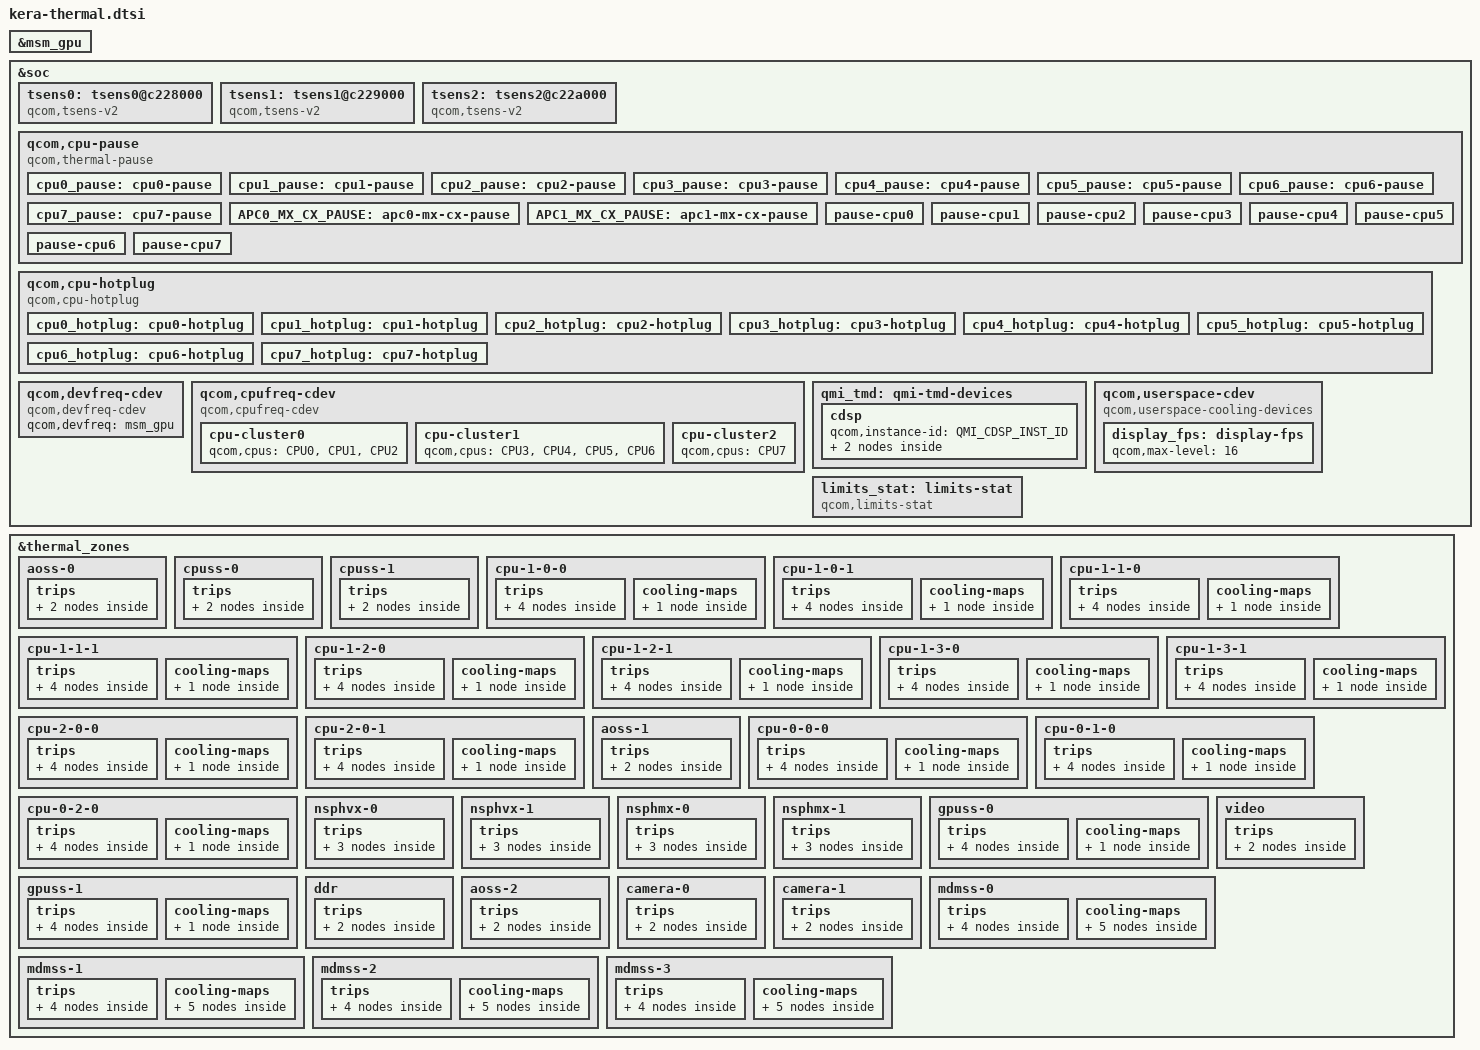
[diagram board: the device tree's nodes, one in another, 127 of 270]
// SPDX-License-Identifier: BSD-3-Clause
/*
 * Copyright (c) 2024-2025 Qualcomm Innovation Center, Inc. All rights reserved.
 */

#include <dt-bindings/thermal/thermal_qti.h>

&msm_gpu {
	#cooling-cells = <2>;
};

&soc {
	tsens0: tsens0@c228000 {
		compatible = "qcom,tsens-v2";
		reg = <0xc228000 0x1ff>, /* TM */
			  <0xc222000 0x1ff>; /* SROT */
		#qcom,sensors = <13>;
		interrupts = <GIC_SPI 506 IRQ_TYPE_LEVEL_HIGH>,
			<GIC_SPI 560 IRQ_TYPE_LEVEL_HIGH>;
		interrupt-names = "uplow","critical";
		#thermal-sensor-cells = <1>;
	};

	tsens1: tsens1@c229000 {
		compatible = "qcom,tsens-v2";
		reg = <0xc229000 0x1ff>, /* TM */
			  <0xc223000 0x1ff>; /* SROT */
		#qcom,sensors = <14>;
		interrupts = <GIC_SPI 507 IRQ_TYPE_LEVEL_HIGH>,
			<GIC_SPI 561 IRQ_TYPE_LEVEL_HIGH>;
		interrupt-names = "uplow","critical";
		#thermal-sensor-cells = <1>;
	};

	tsens2: tsens2@c22a000 {
		compatible = "qcom,tsens-v2";
		reg = <0xc22a000 0x1ff>, /* TM */
			  <0xc224000 0x1ff>; /* SROT */
		#qcom,sensors = <5>;
		interrupts = <GIC_SPI 508 IRQ_TYPE_LEVEL_HIGH>,
			<GIC_SPI 562 IRQ_TYPE_LEVEL_HIGH>;
		interrupt-names = "uplow","critical";
		#thermal-sensor-cells = <1>;
	};

	qcom,cpu-pause {
		compatible = "qcom,thermal-pause";

		cpu0_pause: cpu0-pause {
			qcom,cpus = <&CPU0>;
			qcom,cdev-alias = "thermal-pause-1";
			#cooling-cells = <2>;
		};

		cpu1_pause: cpu1-pause {
			qcom,cpus = <&CPU1>;
			qcom,cdev-alias = "thermal-pause-2";
			#cooling-cells = <2>;
		};

		cpu2_pause: cpu2-pause {
			qcom,cpus = <&CPU2>;
			qcom,cdev-alias = "thermal-pause-4";
			#cooling-cells = <2>;
		};

		cpu3_pause: cpu3-pause {
			qcom,cpus = <&CPU3>;
			qcom,cdev-alias = "thermal-pause-8";
			#cooling-cells = <2>;
		};

		cpu4_pause: cpu4-pause {
			qcom,cpus = <&CPU4>;
			qcom,cdev-alias = "thermal-pause-10";
			#cooling-cells = <2>;
		};

		cpu5_pause: cpu5-pause {
			qcom,cpus = <&CPU5>;
			qcom,cdev-alias = "thermal-pause-20";
			#cooling-cells = <2>;
		};

		cpu6_pause: cpu6-pause {
			qcom,cpus = <&CPU6>;
			qcom,cdev-alias = "thermal-pause-40";
			#cooling-cells = <2>;
		};

		cpu7_pause: cpu7-pause {
			qcom,cpus = <&CPU7>;
			qcom,cdev-alias = "thermal-pause-80";
			#cooling-cells = <2>;
		};

		APC0_MX_CX_PAUSE: apc0-mx-cx-pause {
			qcom,cpus = <&CPU2 &CPU3 &CPU4 &CPU5>;
			qcom,cdev-alias = "thermal-pause-3C";
			#cooling-cells = <2>;
		};

		APC1_MX_CX_PAUSE: apc1-mx-cx-pause {
			qcom,cpus = <&CPU6 &CPU7>;
			qcom,cdev-alias = "thermal-pause-C0";
			#cooling-cells = <2>;
		};

		/* Thermal-engine cooling devices */
		pause-cpu0 {
			qcom,cpus = <&CPU0>;
			qcom,cdev-alias = "pause-cpu0";
		};

		pause-cpu1 {
			qcom,cpus = <&CPU1>;
			qcom,cdev-alias = "pause-cpu1";
		};

		pause-cpu2 {
			qcom,cpus = <&CPU2>;
			qcom,cdev-alias = "pause-cpu2";
		};

		pause-cpu3 {
			qcom,cpus = <&CPU3>;
			qcom,cdev-alias = "pause-cpu3";
		};

		pause-cpu4 {
			qcom,cpus = <&CPU4>;
			qcom,cdev-alias = "pause-cpu4";
		};

		pause-cpu5 {
			qcom,cpus = <&CPU5>;
			qcom,cdev-alias = "pause-cpu5";
		};

		pause-cpu6 {
			qcom,cpus = <&CPU6>;
			qcom,cdev-alias = "pause-cpu6";
		};

		pause-cpu7 {
			qcom,cpus = <&CPU7>;
			qcom,cdev-alias = "pause-cpu7";
		};
	};

	qcom,cpu-hotplug {
		compatible = "qcom,cpu-hotplug";

		cpu0_hotplug: cpu0-hotplug {
			qcom,cpu = <&CPU0>;
			qcom,cdev-alias = "cpu-hotplug0";
			#cooling-cells = <2>;
		};

		cpu1_hotplug: cpu1-hotplug {
			qcom,cpu = <&CPU1>;
			qcom,cdev-alias = "cpu-hotplug1";
			#cooling-cells = <2>;
		};

		cpu2_hotplug: cpu2-hotplug {
			qcom,cpu = <&CPU2>;
			qcom,cdev-alias = "cpu-hotplug2";
			#cooling-cells = <2>;
		};

		cpu3_hotplug: cpu3-hotplug {
			qcom,cpu = <&CPU3>;
			qcom,cdev-alias = "cpu-hotplug3";
			#cooling-cells = <2>;
		};

		cpu4_hotplug: cpu4-hotplug {
			qcom,cpu = <&CPU4>;
			qcom,cdev-alias = "cpu-hotplug4";
			#cooling-cells = <2>;
		};

		cpu5_hotplug: cpu5-hotplug {
			qcom,cpu = <&CPU5>;
			qcom,cdev-alias = "cpu-hotplug5";
			#cooling-cells = <2>;
		};

		cpu6_hotplug: cpu6-hotplug {
			qcom,cpu = <&CPU6>;
			qcom,cdev-alias = "cpu-hotplug6";
			#cooling-cells = <2>;
		};

		cpu7_hotplug: cpu7-hotplug {
			qcom,cpu = <&CPU7>;
			qcom,cdev-alias = "cpu-hotplug7";
			#cooling-cells = <2>;
		};
	};

	qcom,devfreq-cdev {
		compatible = "qcom,devfreq-cdev";
		qcom,devfreq = <&msm_gpu>;
	};

	qcom,cpufreq-cdev {
		compatible = "qcom,cpufreq-cdev";

		cpu-cluster0 {
			qcom,cpus = <&CPU0 &CPU1 &CPU2>;
		};

		cpu-cluster1 {
			qcom,cpus = <&CPU3 &CPU4 &CPU5 &CPU6>;
		};

		cpu-cluster2 {
			qcom,cpus = <&CPU7>;
		};
	};

	qmi_tmd: qmi-tmd-devices {
		cdsp {
			qcom,instance-id = <QMI_CDSP_INST_ID>;

			cdsp_sw: cdsp {
				qcom,qmi-dev-name = "cdsp_sw";
				#cooling-cells = <2>;
			};

			cdsp_hw: cdsp_hw {
				qcom,qmi-dev-name = "cdsp_hw";
				#cooling-cells = <2>;
			};
		};
	};

	qcom,userspace-cdev {
		compatible = "qcom,userspace-cooling-devices";

		display_fps: display-fps {
			qcom,max-level = <16>;
			#cooling-cells = <2>;
		};
	};

	limits_stat: limits-stat {
		compatible = "qcom,limits-stat";
		qcom,limits-stat-sensor-names = "aoss-0", "cpuss-0", "cpuss-1",
						"cpu-1-0-0", "cpu-1-0-1", "cpu-1-1-0",
						"cpu-1-1-1", "cpu-1-2-0", "cpu-1-2-1",
						"cpu-1-3-0", "cpu-1-3-1", "cpu-2-0-0", "cpu-2-0-1",
						"aoss-1", "cpu-0-0-0", "cpu-0-1-0", "cpu-0-2-0",
						"nsphvx-0", "nsphvx-1", "nsphmx-0", "nsphmx-1",
						"gpuss-0", "gpuss-1", "video", "ddr", "camera-0",
						"camera-1", "aoss-2", "mdmss-0", "mdmss-1",
						"mdmss-2", "mdmss-3";
	};
};

#include "sun-thermal-modem.dtsi"

&thermal_zones {
	aoss-0 {
		polling-delay-passive = <0>;
		polling-delay = <0>;
		thermal-sensors = <&tsens0 0>;

		trips {
			trip-point0 {
				temperature = <125000>;
				hysteresis = <1000>;
				type = "passive";
			};

			trip-point1 {
				temperature = <115000>;
				hysteresis = <0>;
				type = "hot";
			};
		};
	};

	cpuss-0 {
		polling-delay-passive = <0>;
		polling-delay = <0>;
		thermal-sensors = <&tsens0 1>;

		trips {
			trip-point0 {
				temperature = <125000>;
				hysteresis = <1000>;
				type = "passive";
			};

			trip-point1 {
				temperature = <115000>;
				hysteresis = <0>;
				type = "hot";
			};
		};
	};

	cpuss-1 {
		polling-delay-passive = <0>;
		polling-delay = <0>;
		thermal-sensors = <&tsens0 2>;

		trips {
			trip-point0 {
				temperature = <125000>;
				hysteresis = <1000>;
				type = "passive";
			};

			trip-point1 {
				temperature = <115000>;
				hysteresis = <0>;
				type = "hot";
			};
		};
	};

	cpu-1-0-0 {
		polling-delay-passive = <0>;
		polling-delay = <0>;
		thermal-sensors = <&tsens0 3>;

		trips {
			trip-point0 {
				temperature = <125000>;
				hysteresis = <1000>;
				type = "passive";
			};

			trip-point1 {
				temperature = <125000>;
				hysteresis = <1000>;
				type = "passive";
			};

			cpu2_emerg0: cpu2-emerg0-cfg {
				temperature = <110000>;
				hysteresis = <10000>;
				type = "passive";
			};

			trip-point2 {
				temperature = <115000>;
				hysteresis = <0>;
				type = "hot";
			};
		};

		cooling-maps {
			cpu100_cdev {
				trip = <&cpu2_emerg0>;
				cooling-device = <&cpu2_pause 1 1>;
			};
		};
	};

	cpu-1-0-1 {
		polling-delay-passive = <0>;
		polling-delay = <0>;
		thermal-sensors = <&tsens0 4>;

		trips {
			trip-point0 {
				temperature = <125000>;
				hysteresis = <1000>;
				type = "passive";
			};

			trip-point1 {
				temperature = <125000>;
				hysteresis = <1000>;
				type = "passive";
			};

			cpu2_emerg1: cpu2-emerg1-cfg {
				temperature = <110000>;
				hysteresis = <10000>;
				type = "passive";
			};

			trip-point2 {
				temperature = <115000>;
				hysteresis = <0>;
				type = "hot";
			};
		};

		cooling-maps {
			cpu101_cdev {
				trip = <&cpu2_emerg1>;
				cooling-device = <&cpu2_pause 1 1>;
			};
		};
	};


	cpu-1-1-0 {
		polling-delay-passive = <0>;
		polling-delay = <0>;
		thermal-sensors = <&tsens0 5>;

		trips {
			trip-point0 {
				temperature = <125000>;
				hysteresis = <1000>;
				type = "passive";
			};

			trip-point1 {
				temperature = <125000>;
				hysteresis = <1000>;
				type = "passive";
			};

			cpu3_emerg0: cpu3-emerg0-cfg {
				temperature = <110000>;
				hysteresis = <10000>;
				type = "passive";
			};

			trip-point2 {
				temperature = <115000>;
				hysteresis = <0>;
				type = "hot";
			};
		};

		cooling-maps {
			cpu110_cdev {
				trip = <&cpu3_emerg0>;
				cooling-device = <&cpu3_pause 1 1>;
			};
		};
	};

	cpu-1-1-1 {
		polling-delay-passive = <0>;
		polling-delay = <0>;
		thermal-sensors = <&tsens0 6>;

		trips {
			trip-point0 {
				temperature = <125000>;
				hysteresis = <1000>;
				type = "passive";
			};

			trip-point1 {
				temperature = <125000>;
				hysteresis = <1000>;
				type = "passive";
			};

			cpu3_emerg1: cpu3-emerg1-cfg {
				temperature = <110000>;
				hysteresis = <10000>;
				type = "passive";
			};

			trip-point2 {
				temperature = <115000>;
				hysteresis = <0>;
				type = "hot";
			};
		};

		cooling-maps {
			cpu111_cdev {
				trip = <&cpu3_emerg1>;
				cooling-device = <&cpu3_pause 1 1>;
			};
		};
	};

	cpu-1-2-0 {
		polling-delay-passive = <0>;
		polling-delay = <0>;
		thermal-sensors = <&tsens0 7>;

		trips {
			trip-point0 {
				temperature = <125000>;
				hysteresis = <1000>;
				type = "passive";
			};

			trip-point1 {
				temperature = <125000>;
				hysteresis = <1000>;
				type = "passive";
			};

			cpu4_emerg0: cpu4-emerg0-cfg {
				temperature = <110000>;
				hysteresis = <10000>;
				type = "passive";
			};

			trip-point2 {
				temperature = <115000>;
				hysteresis = <0>;
				type = "hot";
			};
		};

		cooling-maps {
			cpu120_cdev {
				trip = <&cpu4_emerg0>;
				cooling-device = <&cpu4_pause 1 1>;
			};
		};
	};

	cpu-1-2-1 {
		polling-delay-passive = <0>;
		polling-delay = <0>;
		thermal-sensors = <&tsens0 8>;

		trips {
			trip-point0 {
				temperature = <125000>;
				hysteresis = <1000>;
				type = "passive";
			};

			trip-point1 {
				temperature = <125000>;
				hysteresis = <1000>;
				type = "passive";
			};

			cpu4_emerg1: cpu4-emerg1-cfg {
				temperature = <110000>;
				hysteresis = <10000>;
				type = "passive";
			};

			trip-point2 {
				temperature = <115000>;
				hysteresis = <0>;
				type = "hot";
			};
		};

		cooling-maps {
			cpu121_cdev {
				trip = <&cpu4_emerg1>;
				cooling-device = <&cpu4_pause 1 1>;
			};
		};
	};

	cpu-1-3-0 {
		polling-delay-passive = <0>;
		polling-delay = <0>;
		thermal-sensors = <&tsens0 9>;

		trips {
			trip-point0 {
				temperature = <125000>;
				hysteresis = <1000>;
				type = "passive";
			};

			trip-point1 {
				temperature = <125000>;
				hysteresis = <1000>;
				type = "passive";
			};

			cpu5_emerg0: cpu5-emerg0-cfg {
				temperature = <110000>;
				hysteresis = <10000>;
				type = "passive";
			};

			trip-point4 {
				temperature = <115000>;
				hysteresis = <0>;
				type = "hot";
			};
		};

		cooling-maps {
			cpu130_cdev {
				trip = <&cpu5_emerg0>;
				cooling-device = <&cpu5_pause 1 1>;
			};
		};
	};

	cpu-1-3-1 {
		polling-delay-passive = <0>;
		polling-delay = <0>;
		thermal-sensors = <&tsens0 10>;

		trips {
			trip-point0 {
				temperature = <125000>;
				hysteresis = <1000>;
				type = "passive";
			};

			trip-point1 {
				temperature = <125000>;
				hysteresis = <1000>;
				type = "passive";
			};

			cpu5_emerg1: cpu5-emerg1-cfg {
				temperature = <110000>;
				hysteresis = <10000>;
				type = "passive";
			};

			trip-point2 {
				temperature = <115000>;
				hysteresis = <0>;
				type = "hot";
			};
		};

		cooling-maps {
			cpu131_cdev {
				trip = <&cpu5_emerg1>;
				cooling-device = <&cpu5_pause 1 1>;
			};
		};
	};

	cpu-2-0-0 {
		polling-delay-passive = <0>;
		polling-delay = <0>;
		thermal-sensors = <&tsens0 11>;

		trips {
			trip-point0 {
				temperature = <125000>;
				hysteresis = <1000>;
				type = "passive";
			};

			trip-point1 {
				temperature = <125000>;
				hysteresis = <1000>;
				type = "passive";
			};

			cpu7_emerg0: cpu7-emerg0-cfg {
				temperature = <110000>;
				hysteresis = <10000>;
				type = "passive";
			};

			trip-point2 {
				temperature = <115000>;
				hysteresis = <0>;
				type = "hot";
			};
		};

		cooling-maps {
			cpu200_cdev {
				trip = <&cpu7_emerg0>;
				cooling-device = <&cpu7_pause 1 1>;
			};
		};
	};

	cpu-2-0-1 {
		polling-delay-passive = <0>;
		polling-delay = <0>;
		thermal-sensors = <&tsens0 12>;

		trips {
			trip-point0 {
				temperature = <125000>;
				hysteresis = <1000>;
				type = "passive";
			};

			trip-point1 {
				temperature = <125000>;
				hysteresis = <1000>;
				type = "passive";
			};

			cpu7_emerg1: cpu7-emerg0-cfg {
				temperature = <110000>;
				hysteresis = <10000>;
				type = "passive";
			};

			trip-point2 {
				temperature = <115000>;
				hysteresis = <0>;
				type = "hot";
			};
		};

		cooling-maps {
			cpu201_cdev {
				trip = <&cpu7_emerg1>;
				cooling-device = <&cpu7_pause 1 1>;
			};
		};
	};

	aoss-1 {
		polling-delay-passive = <0>;
		polling-delay = <0>;
		thermal-sensors = <&tsens1 0>;

		trips {
			trip-point0 {
				temperature = <125000>;
				hysteresis = <1000>;
				type = "passive";
			};

			trip-point1 {
				temperature = <115000>;
				hysteresis = <0>;
				type = "hot";
			};
		};
	};

	cpu-0-0-0 {
		polling-delay-passive = <0>;
		polling-delay = <0>;
		thermal-sensors = <&tsens1 1>;

		trips {
			trip-point0 {
				temperature = <125000>;
				hysteresis = <1000>;
				type = "passive";
			};

			trip-point1 {
				temperature = <125000>;
				hysteresis = <1000>;
				type = "passive";
			};

			cpu0_emerg0: cpu0-emerg0-cfg {
				temperature = <110000>;
				hysteresis = <10000>;
				type = "passive";
			};

			trip-point2 {
				temperature = <115000>;
				hysteresis = <0>;
				type = "hot";
			};
		};

		cooling-maps {
			cpu000_cdev {
				trip = <&cpu0_emerg0>;
				cooling-device = <&cpu0_pause 1 1>;
			};
		};
	};

	cpu-0-1-0 {
		polling-delay-passive = <0>;
		polling-delay = <0>;
		thermal-sensors = <&tsens1 2>;

		trips {
			trip-point0 {
				temperature = <125000>;
				hysteresis = <1000>;
				type = "passive";
			};

			trip-point1 {
				temperature = <125000>;
				hysteresis = <1000>;
				type = "passive";
			};

			cpu1_emerg0: cpu1-emerg0-cfg {
				temperature = <110000>;
				hysteresis = <10000>;
				type = "passive";
			};

			trip-point2 {
				temperature = <115000>;
				hysteresis = <0>;
				type = "hot";
			};
		};

		cooling-maps {
			cpu010_cdev {
				trip = <&cpu1_emerg0>;
				cooling-device = <&cpu1_pause 1 1>;
			};
		};
	};

	cpu-0-2-0 {
		polling-delay-passive = <0>;
		polling-delay = <0>;
		thermal-sensors = <&tsens1 3>;

		trips {
			trip-point0 {
				temperature = <125000>;
				hysteresis = <1000>;
				type = "passive";
			};

			trip-point1 {
				temperature = <125000>;
				hysteresis = <1000>;
				type = "passive";
			};

			cpu6_emerg0: cpu6-emerg0-cfg {
				temperature = <110000>;
				hysteresis = <10000>;
				type = "passive";
			};

			trip-point2 {
				temperature = <115000>;
				hysteresis = <0>;
				type = "hot";
			};
		};

		cooling-maps {
			cpu140_cdev {
				trip = <&cpu6_emerg0>;
				cooling-device = <&cpu6_pause 1 1>;
			};
		};
	};

	nsphvx-0 {
		polling-delay-passive = <0>;
		polling-delay = <0>;
		thermal-sensors = <&tsens1 4>;

		trips {
			trip-point0 {
				temperature = <125000>;
				hysteresis = <1000>;
				type = "passive";
			};

			trip-point1 {
				temperature = <125000>;
				hysteresis = <1000>;
				type = "passive";
			};

			trip-point2 {
				temperature = <115000>;
				hysteresis = <0>;
				type = "hot";
			};
		};
	};

	nsphvx-1 {
		polling-delay-passive = <0>;
		polling-delay = <0>;
		thermal-sensors = <&tsens1 5>;

		trips {
			trip-point0 {
				temperature = <125000>;
				hysteresis = <1000>;
				type = "passive";
			};

			trip-point1 {
				temperature = <125000>;
				hysteresis = <1000>;
				type = "passive";
			};

			trip-point2 {
				temperature = <115000>;
				hysteresis = <0>;
				type = "hot";
			};
		};
	};

	nsphmx-0 {
		polling-delay-passive = <0>;
		polling-delay = <0>;
		thermal-sensors = <&tsens1 6>;

		trips {
			trip-point0 {
				temperature = <125000>;
				hysteresis = <1000>;
				type = "passive";
			};

			trip-point1 {
				temperature = <125000>;
				hysteresis = <1000>;
				type = "passive";
			};

			trip-point2 {
				temperature = <115000>;
				hysteresis = <0>;
				type = "hot";
			};
		};
	};

	nsphmx-1 {
		polling-delay-passive = <0>;
		polling-delay = <0>;
		thermal-sensors = <&tsens1 7>;

		trips {
			trip-point0 {
				temperature = <125000>;
				hysteresis = <1000>;
				type = "passive";
			};

			trip-point1 {
				temperature = <125000>;
				hysteresis = <1000>;
				type = "passive";
			};

			trip-point2 {
				temperature = <115000>;
				hysteresis = <0>;
				type = "hot";
			};
		};
	};


	gpuss-0 {
		polling-delay-passive = <10>;
		polling-delay = <0>;
		thermal-sensors = <&tsens1 8>;

		trips {
			trip-point0 {
				temperature = <125000>;
				hysteresis = <1000>;
				type = "passive";
			};

			trip-point1 {
				temperature = <125000>;
				hysteresis = <1000>;
				type = "passive";
			};

			gpu0_tj_cfg: tj_cfg {
				temperature = <95000>;
				hysteresis = <5000>;
				type = "passive";
			};

			trip-point2 {
				temperature = <115000>;
				hysteresis = <0>;
				type = "hot";
			};
		};

		cooling-maps {
			gpu0_cdev {
				trip = <&gpu0_tj_cfg>;
				cooling-device = <&msm_gpu 0 THERMAL_NO_LIMIT>;
			};
		};
	};

	gpuss-1 {
		polling-delay-passive = <10>;
		polling-delay = <0>;
		thermal-sensors = <&tsens1 9>;

		trips {
			trip-point0 {
				temperature = <125000>;
				hysteresis = <1000>;
				type = "passive";
			};

			trip-point1 {
				temperature = <125000>;
				hysteresis = <1000>;
				type = "passive";
			};

			gpu1_tj_cfg: tj_cfg {
				temperature = <95000>;
				hysteresis = <5000>;
				type = "passive";
			};

			trip-point2 {
				temperature = <115000>;
				hysteresis = <0>;
				type = "hot";
			};
		};

		cooling-maps {
			gpu1_cdev {
				trip = <&gpu1_tj_cfg>;
				cooling-device = <&msm_gpu 0 THERMAL_NO_LIMIT>;
			};
		};
	};

	video {
		polling-delay-passive = <0>;
		polling-delay = <0>;
		thermal-sensors = <&tsens1 10>;

		trips {
			trip-point0 {
				temperature = <125000>;
				hysteresis = <1000>;
				type = "passive";
			};

			trip-point1 {
				temperature = <115000>;
				hysteresis = <0>;
				type = "hot";
			};

		};
	};

	ddr {
		polling-delay-passive = <0>;
		polling-delay = <0>;
		thermal-sensors = <&tsens1 11>;

		trips {
			trip-point0 {
				temperature = <125000>;
				hysteresis = <1000>;
				type = "passive";
			};

			trip-point1 {
				temperature = <115000>;
				hysteresis = <0>;
				type = "hot";
			};
		};
	};

	aoss-2 {
		polling-delay-passive = <0>;
		polling-delay = <0>;
		thermal-sensors = <&tsens2 0>;

		trips {
			trip-point0 {
				temperature = <125000>;
				hysteresis = <1000>;
				type = "passive";
			};

			trip-point1 {
				temperature = <115000>;
				hysteresis = <0>;
				type = "hot";
			};
		};
	};

	camera-0 {
		polling-delay-passive = <0>;
		polling-delay = <0>;
		thermal-sensors = <&tsens1 12>;

		trips {
			trip-point0 {
				temperature = <125000>;
				hysteresis = <1000>;
				type = "passive";
			};

			trip-point1 {
				temperature = <115000>;
				hysteresis = <0>;
				type = "hot";
			};
		};
	};

	camera-1 {
		polling-delay-passive = <0>;
		polling-delay = <0>;
		thermal-sensors = <&tsens1 13>;

		trips {
			trip-point0 {
				temperature = <125000>;
				hysteresis = <1000>;
				type = "passive";
			};

			trip-point1 {
				temperature = <115000>;
				hysteresis = <0>;
				type = "hot";
			};
		};
	};

	aoss-2 {
		polling-delay-passive = <0>;
		polling-delay = <0>;
		thermal-sensors = <&tsens2 0>;

		trips {
			trip-point0 {
				temperature = <125000>;
				hysteresis = <1000>;
				type = "passive";
			};

			trip-point1 {
				temperature = <115000>;
				hysteresis = <0>;
				type = "hot";
			};
		};
	};

	mdmss-0 {
		polling-delay-passive = <100>;
		polling-delay = <0>;
		thermal-sensors = <&tsens2 1>;

		trips {
			trip-point0 {
				temperature = <125000>;
				hysteresis = <1000>;
				type = "passive";
			};

			mdmss0_config0: mdmss0-config0 {
				temperature = <102000>;
				hysteresis = <3000>;
				type = "passive";
			};

			mdmss0_config1: mdmss0-config1 {
				temperature = <105000>;
				hysteresis = <3000>;
				type = "passive";
			};

			trip-point1 {
				temperature = <115000>;
				hysteresis = <0>;
				type = "hot";
			};
		};

		cooling-maps {
			lte_cdev0 {
				trip = <&mdmss0_config0>;
				cooling-device = <&modem_lte_dsc 8 8>;
			};

			nr_scg_cdev0 {
				trip = <&mdmss0_config0>;
				cooling-device = <&modem_nr_scg_dsc 100 100>;
			};

			nr_cdev0 {
				trip = <&mdmss0_config0>;
				cooling-device = <&modem_nr_dsc 10 10>;
			};

			lte_cdev2 {
				trip = <&mdmss0_config1>;
				cooling-device = <&modem_lte_dsc 255 255>;
			};

			nr_cdev2 {
				trip = <&mdmss0_config1>;
				cooling-device = <&modem_nr_dsc 255 255>;
			};
		};
	};

	mdmss-1 {
		polling-delay-passive = <100>;
		polling-delay = <0>;
		thermal-sensors = <&tsens2 2>;

		trips {
			trip-point0 {
				temperature = <125000>;
				hysteresis = <1000>;
				type = "passive";
			};

			mdmss1_config0: mdmss1-config0 {
				temperature = <102000>;
				hysteresis = <3000>;
				type = "passive";
			};

			mdmss1_config1: mdmss1-config1 {
				temperature = <105000>;
				hysteresis = <3000>;
				type = "passive";
			};

			trip-point1 {
				temperature = <115000>;
				hysteresis = <0>;
				type = "hot";
			};
		};

		cooling-maps {
			lte_cdev0 {
				trip = <&mdmss1_config0>;
				cooling-device = <&modem_lte_dsc 8 8>;
			};

			nr_scg_cdev0 {
				trip = <&mdmss1_config0>;
				cooling-device = <&modem_nr_scg_dsc 100 100>;
			};

			nr_cdev0 {
				trip = <&mdmss1_config0>;
				cooling-device = <&modem_nr_dsc 10 10>;
			};

			lte_cdev2 {
				trip = <&mdmss1_config1>;
				cooling-device = <&modem_lte_dsc 255 255>;
			};

			nr_cdev2 {
				trip = <&mdmss1_config1>;
				cooling-device = <&modem_nr_dsc 255 255>;
			};
		};
	};

	mdmss-2 {
		polling-delay-passive = <100>;
		polling-delay = <0>;
		thermal-sensors = <&tsens2 3>;

		trips {
			trip-point0 {
				temperature = <125000>;
				hysteresis = <1000>;
				type = "passive";
			};

			mdmss2_config0: mdmss2-config0 {
				temperature = <102000>;
				hysteresis = <3000>;
				type = "passive";
			};

			mdmss2_config1: mdmss2-config1 {
				temperature = <105000>;
				hysteresis = <3000>;
				type = "passive";
			};

			trip-point1 {
				temperature = <115000>;
				hysteresis = <0>;
				type = "hot";
			};
		};

		cooling-maps {
			lte_cdev0 {
				trip = <&mdmss2_config0>;
				cooling-device = <&modem_lte_dsc 8 8>;
			};

			nr_scg_cdev0 {
				trip = <&mdmss2_config0>;
				cooling-device = <&modem_nr_scg_dsc 100 100>;
			};

			nr_cdev0 {
				trip = <&mdmss2_config0>;
				cooling-device = <&modem_nr_dsc 10 10>;
			};

			lte_cdev2 {
				trip = <&mdmss2_config1>;
				cooling-device = <&modem_lte_dsc 255 255>;
			};

			nr_cdev2 {
				trip = <&mdmss2_config1>;
				cooling-device = <&modem_nr_dsc 255 255>;
			};
		};
	};

	mdmss-3 {
		polling-delay-passive = <100>;
		polling-delay = <0>;
		thermal-sensors = <&tsens2 4>;

		trips {
			trip-point0 {
				temperature = <125000>;
				hysteresis = <1000>;
				type = "passive";
			};

			mdmss3_config0: mdmss3-config0 {
				temperature = <102000>;
				hysteresis = <3000>;
				type = "passive";
			};

			mdmss3_config1: mdmss3-config1 {
				temperature = <105000>;
				hysteresis = <3000>;
				type = "passive";
			};

			trip-point1 {
				temperature = <115000>;
				hysteresis = <0>;
				type = "hot";
			};
		};

		cooling-maps {
			lte_cdev0 {
				trip = <&mdmss3_config0>;
				cooling-device = <&modem_lte_dsc 8 8>;
			};

			nr_scg_cdev0 {
				trip = <&mdmss3_config0>;
				cooling-device = <&modem_nr_scg_dsc 100 100>;
			};

			nr_cdev0 {
				trip = <&mdmss3_config0>;
				cooling-device = <&modem_nr_dsc 10 10>;
			};

			lte_cdev2 {
				trip = <&mdmss3_config1>;
				cooling-device = <&modem_lte_dsc 255 255>;
			};

			nr_cdev2 {
				trip = <&mdmss3_config1>;
				cooling-device = <&modem_nr_dsc 255 255>;
			};
		};
	};
};
